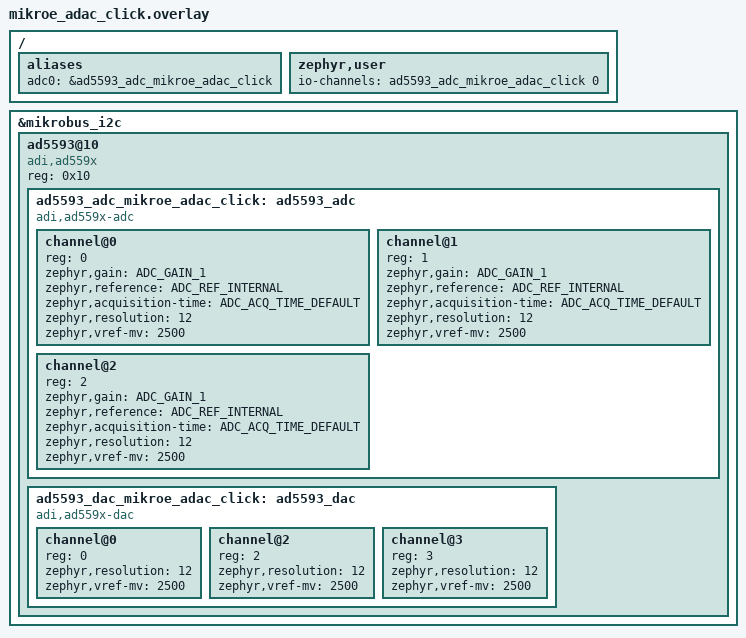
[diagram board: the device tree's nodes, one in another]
/*
 * Copyright (c) 2026 Analog Devices, Inc.
 * SPDX-License-Identifier: Apache-2.0
 */

#include <zephyr/dt-bindings/adc/adc.h>
#include <zephyr/dt-bindings/gpio/mikro-bus.h>

/ {
	aliases {
		adc0 = &ad5593_adc_mikroe_adac_click;
	};

	zephyr,user {
		io-channels = <&ad5593_adc_mikroe_adac_click 0>;
	};
};

&mikrobus_i2c {
	status = "okay";

	ad5593@10 {
		compatible = "adi,ad559x";
		reg = <0x10>;

		ad5593_adc_mikroe_adac_click: ad5593_adc {
			compatible = "adi,ad559x-adc";
			#io-channel-cells = <1>;
			#address-cells = <1>;
			#size-cells = <0>;

			channel@0 {
				reg = <0>;
				zephyr,gain = "ADC_GAIN_1";
				zephyr,reference = "ADC_REF_INTERNAL";
				zephyr,acquisition-time = <ADC_ACQ_TIME_DEFAULT>;
				zephyr,resolution = <12>;
				zephyr,vref-mv = <2500>;
			};

			channel@1 {
				reg = <1>;
				zephyr,gain = "ADC_GAIN_1";
				zephyr,reference = "ADC_REF_INTERNAL";
				zephyr,acquisition-time = <ADC_ACQ_TIME_DEFAULT>;
				zephyr,resolution = <12>;
				zephyr,vref-mv = <2500>;
			};

			channel@2 {
				reg = <2>;
				zephyr,gain = "ADC_GAIN_1";
				zephyr,reference = "ADC_REF_INTERNAL";
				zephyr,acquisition-time = <ADC_ACQ_TIME_DEFAULT>;
				zephyr,resolution = <12>;
				zephyr,vref-mv = <2500>;
			};
		};

		ad5593_dac_mikroe_adac_click: ad5593_dac {
			compatible = "adi,ad559x-dac";
			#io-channel-cells = <1>;
			#address-cells = <1>;
			#size-cells = <0>;

			channel@0 {
				reg = <0>;
				zephyr,resolution = <12>;
				zephyr,vref-mv = <2500>;
			};

			channel@2 {
				reg = <2>;
				zephyr,resolution = <12>;
				zephyr,vref-mv = <2500>;
			};

			channel@3 {
				reg = <3>;
				zephyr,resolution = <12>;
				zephyr,vref-mv = <2500>;
			};
		};
	};
};
